# R7FA0E303 register map
Vendor: Renesas Electronics Corporation; Series: RA0; File version: 1.00.00
CPU: CM23 r1p0, little endian, no MPU, no FPU, VTOR, 2 interrupt priority bits, 64 interrupts
Registers are 16-bit, read-write, reset 0x0 unless marked. A register's access mark holds for its fields unless they carry their own. Offsets are from the block's base; [hi:lo] are bit positions; {n}, {i} and the like mark numbered series; 'fields as' and 'values as' point back to an identical list.

## ICU — Interrupt Controller
Base 0x40006000
{0x0+i} IRQCR{i} (i=0..5) 8-bit — IRQ Control Register {i}
  [1:0] IRQMD — IRQi Detection Sense Select
    0=Falling edge; 1=Rising edge; 2=Rising and falling edges; 3=Setting prohibited
0x100 NMICR 8-bit — NMI Pin Interrupt Control Register
  [0] NMIMD — NMI Detection Set
    0=Falling edge; 1=Rising edge
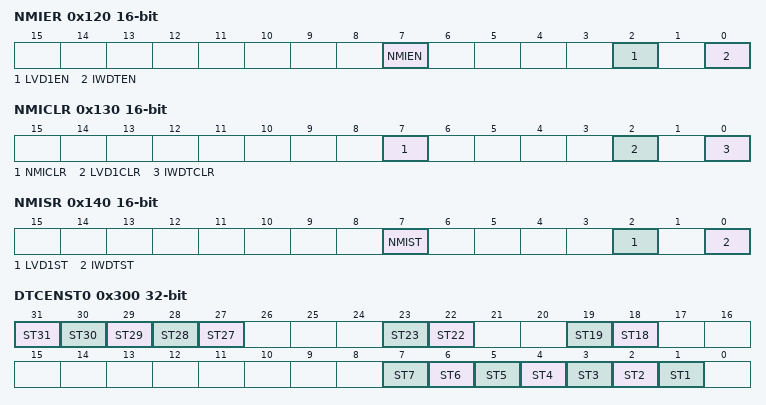
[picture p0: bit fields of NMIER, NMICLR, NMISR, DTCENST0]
0x120 NMIER — Non-maskable Interrupt Enable Register
  [all] fields
    0=Disabled; 1=Enabled
  [7] NMIEN — NMI Pin Interrupt Enable
  [2] LVD1EN — Voltage Monitor 1 Interrupt Enable
  [0] IWDTEN — IWDT Underflow/Refresh Error Interrupt Enable
0x130 NMICLR — Non-maskable Interrupt Status Clear Register
  [7] NMICLR — NMI Pin Interrupt Status Flag Clear
    0=No effect; 1=Clear the NMISR.NMIST flag
  [2] LVD1CLR — Voltage Monitor 1 Interrupt Status Flag Clear
    0=No effect; 1=Clear the NMISR.LVD1ST flag
  [0] IWDTCLR — IWDT Underflow/Refresh Error Interrupt Status Flag Clear
    0=No effect; 1=Clear the NMISR.IWDTST flag
0x140 NMISR ro — Non-maskable Interrupt Status Register
  [all] fields
    0=Interrupt not requested; 1=Interrupt requested
  [7] NMIST — NMI Pin Interrupt Status Flag
  [2] LVD1ST — Voltage Monitor 1 Interrupt Status Flag
  [0] IWDTST — IWDT Underflow/Refresh Error Interrupt Status Flag
0x300 DTCENST0 32-bit ro — DTC Enable Status Register 0
  [all] fields
    0=DTC Disable by Event number i; 1=DTC Enable by Event number i
  [n] ST{n} (n=27..31) — DTC Enable Status by Event Number i
  [23] ST23 — DTC Enable Status by Event Number i
  [22] ST22 — DTC Enable Status by Event Number i
  [19] ST19 — DTC Enable Status by Event Number i
  [18] ST18 — DTC Enable Status by Event Number i
  [n] ST{n} (n=1..7) — DTC Enable Status by Event Number i
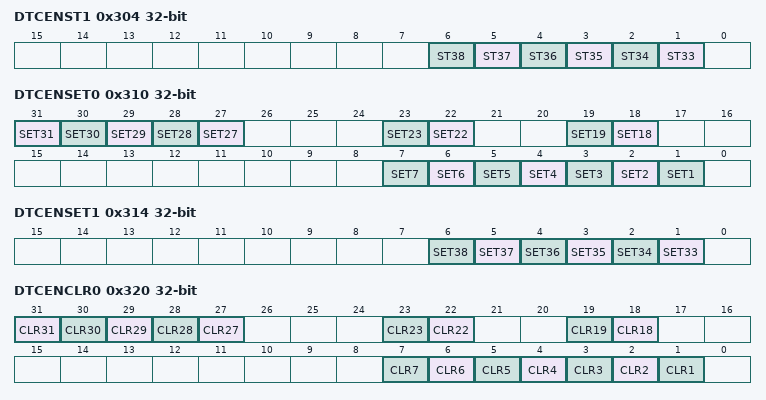
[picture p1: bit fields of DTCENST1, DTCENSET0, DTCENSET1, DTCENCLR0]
0x304 DTCENST1 32-bit ro — DTC Enable Status Register 1
  [all] fields
    values as the fields of DTCENST0
  [n-32] ST{n} (n=33..38) — DTC Enable Status by Event Number i
0x310 DTCENSET0 32-bit — DTC Enable Set Register 0
  [all] fields
    0=No effect; 1=DTC Enable by Event number i
  [n] SET{n} (n=27..31) — DTC Enable Set by Event Number i
  [23] SET23 — DTC Enable Set by Event Number i
  [22] SET22 — DTC Enable Set by Event Number i
  [19] SET19 — DTC Enable Set by Event Number i
  [18] SET18 — DTC Enable Set by Event Number i
  [n] SET{n} (n=1..7) — DTC Enable Set by Event Number i
0x314 DTCENSET1 32-bit — DTC Enable Set Register 1
  [all] fields
    0=No effect; 1=DTC Enable by Event number i
  [n-32] SET{n} (n=33..38) — DTC Enable Set by Event Number i
0x320 DTCENCLR0 32-bit — DTC Enable Clear Register 0
  [all] fields
    0=No effect; 1=DTC Disable by Event number i
  [n] CLR{n} (n=27..31) — DTC Enable Clear by Event Number i
  [23] CLR23 — DTC Enable Clear by Event Number i
  [22] CLR22 — DTC Enable Clear by Event Number i
  [19] CLR19 — DTC Enable Clear by Event Number i
  [18] CLR18 — DTC Enable Clear by Event Number i
  [n] CLR{n} (n=1..7) — DTC Enable Clear by Event Number i
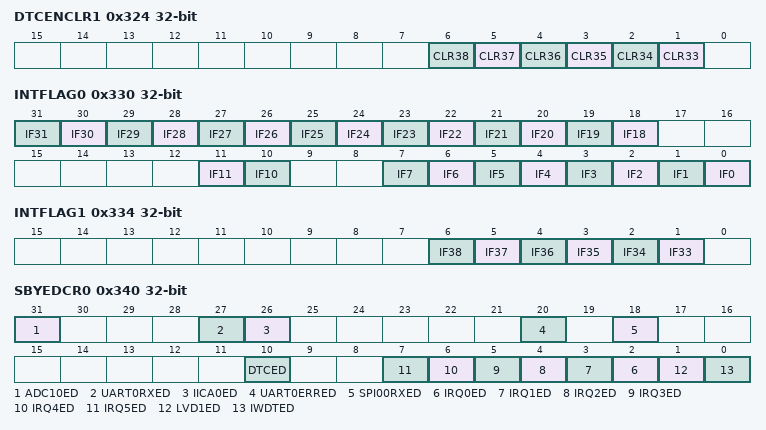
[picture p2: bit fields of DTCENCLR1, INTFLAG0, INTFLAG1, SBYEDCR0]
0x324 DTCENCLR1 32-bit — DTC Enable Clear Register 1
  [all] fields
    0=No effect; 1=DTC Disable by Event number i
  [n-32] CLR{n} (n=33..38) — DTC Enable Clear by Event Number i
0x330 INTFLAG0 32-bit ro — Interrupt Request Flag Monitor Register 0
  [all] fields
    0=Interrupt request of event number i is not being accepted by the ICU; 1=Interrupt request of event number i is being accepted by the ICU
  [n] IF{n} (n=18..31) — Interrupt Request Flag Monitor
  [11] IF11 — Interrupt Request Flag Monitor
  [10] IF10 — Interrupt Request Flag Monitor
  [n] IF{n} (n=0..7) — Interrupt Request Flag Monitor
0x334 INTFLAG1 32-bit ro — Interrupt Request Flag Monitor Register 1
  [all] fields
    0=Interrupt source of event number i is not accepted by the ICU; 1=Interrupt source of event number i is accepted by the ICU
  [n-32] IF{n} (n=33..38) — Interrupt Request Flag Monitor
0x340 SBYEDCR0 32-bit — Software Standby/Snooze End Control Register 0
  [31] ADC10ED — End of A/D Conversion Interrupt Snooze Mode Returns Enable
    0=Snooze Mode returns by End of A/D conversion interrupt disabled; 1=Snooze Mode returns by End of A/D conversion interrupt enabled
  [27] UART0RXED — UART0 Reception Transfer End Interrupt Snooze Mode Returns Enable
    0=Snooze Mode returns by UART0 reception transfer end interrupt disabled; 1=Snooze Mode returns by UART0 reception transfer end interrupt enabled
  [26] IICA0ED — IICA0 Address Match Interrupt Software Standby/Snooze Mode Returns Enable
    0=Software Standby/Snooze Mode returns by IICA0 address match interrupt disabled; 1=Software Standby/Snooze Mode returns by IICA0 address match interrupt enabled
  [20] UART0ERRED — UART0 Reception Communication Error Occurrence Interrupt Snooze Mode Returns Enable
    0=Snooze Mode returns by UART0 reception communication error occurrence interrupt disabled; 1=Snooze Mode returns by UART0 reception communication error occurrence interrupt enabled
  [18] SPI00RXED — SPI00 Transfer End or Buffer Empty Interrupt Snooze Mode Returns Enable
    0=Snooze Mode returns by SPI00 transfer end or buffer empty interrupt disabled; 1=Snooze Mode returns by SPI00 transfer end or buffer empty interrupt enabled
  [10] DTCED — DTC Transfer Complete Interrupt Snooze Mode Returns Enable
    0=Snooze Mode returns by DTC transfer complete interrupt disabled; 1=Snooze Mode returns by DTC transfer complete interrupt enabled
  [n+2] IRQ{n}ED (n=0..5) — IRQ Interrupt Software Standby/Snooze Mode Returns Enable
    0=Software Standby/Snooze mode returns by IRQ{n} interrupt disabled; 1=Software Standby/Snooze mode returns by IRQ{n} interrupt enabled
  [1] LVD1ED — LVD1 Interrupt Software Standby/Snooze Mode Returns Enable
    0=Software Standby/Snooze Mode returns by LVD1 interrupt disabled; 1=Software Standby/Snooze Mode returns by LVD1 interrupt enabled
  [0] IWDTED — IWDT Interrupt Software Standby/Snooze Mode Returns Enable
    0=Software Standby/Snooze Mode returns by IWDT interrupt disabled; 1=Software Standby/Snooze Mode returns by IWDT interrupt enabled
0x344 SBYEDCR1 32-bit — Software Standby/Snooze End Control Register 1
  [1] ITLED — Interval Signal of 32-bit Interval Timer Interrupt Software Standby/Snooze Mode Returns Enable
    0=Software Standby/Snooze Mode returns by Interval signal of 32-bit interval timer interrupt disabled; 1=Software Standby/Snooze Mode returns by Interval signal of 32-bit interval timer interrupt enabled

## Notices in the file
This software is supplied by Renesas Electronics Corporation and is only intended for
use with Renesas products. No other uses are authorized. This software is owned by
Renesas Electronics Corporation and is protected under all applicable laws, including
copyright laws.
THIS SOFTWARE IS PROVIDED "AS IS" AND RENESAS MAKES NO WARRANTIES REGARDING
THIS SOFTWARE, WHETHER EXPRESS, IMPLIED OR STATUTORY, INCLUDING BUT NOT LIMITED TO
WARRANTIES OF MERCHANTABILITY, FITNESS FOR A PARTICULAR PURPOSE AND NON-INFRINGEMENT.
ALL SUCH WARRANTIES ARE EXPRESSLY DISCLAIMED. TO THE MAXIMUM EXTENT PERMITTED NOT
PROHIBITED BY LAW, NEITHER RENESAS ELECTRONICS CORPORATION NOR ANY OF ITS AFFILIATED
COMPANIES SHALL BE LIABLE FOR ANY DIRECT, INDIRECT, SPECIAL, INCIDENTAL OR CONSEQUENTIAL
DAMAGES FOR ANY REASON RELATED TO THIS SOFTWARE, EVEN IF RENESAS OR ITS AFFILIATES HAVE
BEEN ADVISED OF THE POSSIBILITY OF SUCH DAMAGES.
Renesas reserves the right, without notice, to make changes to this software and to
discontinue the availability of this software. By using this software, you agree to
the additional terms and conditions found by accessing the following link:
http://www.renesas.com/disclaimer
